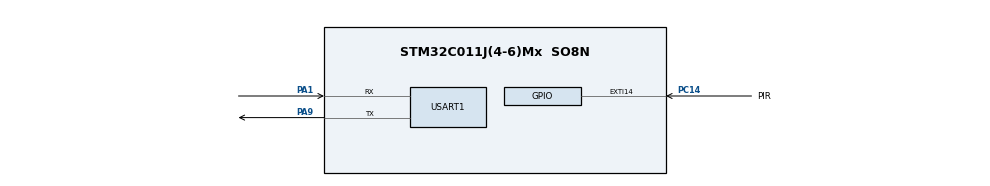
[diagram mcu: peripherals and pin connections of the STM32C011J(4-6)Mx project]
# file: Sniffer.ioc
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Dma.Request0=USART1_TX
Dma.USART1_TX.0.Direction=DMA_MEMORY_TO_PERIPH
Dma.USART1_TX.0.EventEnable=DISABLE
Dma.USART1_TX.0.Instance=DMA1_Channel1
Dma.USART1_TX.0.MemDataAlignment=DMA_MDATAALIGN_BYTE
Dma.USART1_TX.0.MemInc=DMA_MINC_ENABLE
Dma.USART1_TX.0.Mode=DMA_NORMAL
Dma.USART1_TX.0.PeriphDataAlignment=DMA_PDATAALIGN_BYTE
Dma.USART1_TX.0.PeriphInc=DMA_PINC_DISABLE
Dma.USART1_TX.0.Polarity=HAL_DMAMUX_REQ_GEN_RISING
Dma.USART1_TX.0.Priority=DMA_PRIORITY_LOW
Dma.USART1_TX.0.RequestNumber=1
Dma.USART1_TX.0.SignalID=NONE
Dma.USART1_TX.0.SyncEnable=DISABLE
Dma.USART1_TX.0.SyncPolarity=HAL_DMAMUX_SYNC_NO_EVENT
Dma.USART1_TX.0.SyncRequestNumber=1
Dma.USART1_TX.0.SyncSignalID=NONE
Mcu.Family=STM32C0
Mcu.Name=STM32C011J(4-6)Mx
Mcu.Package=SO8N
NVIC.DMA1_Channel1_IRQn=true\:0\:0\:false\:false\:true\:false\:true\:true
NVIC.EXTI4_15_IRQn=true\:0\:0\:false\:false\:true\:true\:true\:true
NVIC.TIM14_IRQn=true\:3\:0\:true\:false\:true\:true\:true\:true
NVIC.TIM16_IRQn=true\:0\:0\:false\:false\:true\:true\:true\:true
PA1.Mode=Asynchronous
PA1.Signal=USART1_RX
PA8__PA11\ [PA9].StandardMode=true
PA9\ [PA11].Mode=Asynchronous
PA9\ [PA11].Signal=USART1_TX
PC14-OSCX_IN\ (PC14).GPIO_Label=PIR
PC14-OSCX_IN\ (PC14).GPIO_ModeDefaultEXTI=GPIO_MODE_IT_RISING_FALLING
PC14-OSCX_IN\ (PC14).Signal=GPXTI14
PC14-OSCX_IN\ (PC14)__PB7.StandardMode=true
PC15-OSCX_OUT\ (PC15)__PA14-BOOT0__PB6.StandardMode=true
PF2-NRST__PA0__PA1__PA2.StandardMode=true
ProjectManager.HeapSize=0x200
ProjectManager.StackSize=0x400
ProjectManager.TargetToolchain=STM32CubeIDE
RCC.ADCFreq_Value=48000000
RCC.AHBFreq_Value=48000000
RCC.CortexFreq_Value=48000000
RCC.EXTERNAL_CLOCK_VALUE=12288000
RCC.HCLKFreq_Value=48000000
RCC.HSE_VALUE=8000000
RCC.HSISYSCLKDivider=RCC_HSI_DIV1
RCC.HSI_VALUE=48000000
RCC.LSE_VALUE=32768
RCC.SYSCLKFreq_VALUE=48000000
TIM14.Period=999
TIM14.Prescaler=47
TIM16.Period=1000
TIM16.Prescaler=47999
TIM3.Prescaler=5
USART1.VirtualMode-Asynchronous=VM_ASYNC
VP_SYS_VS_PINREMAP.Mode=PINREMAP
VP_TIM14_VS_ClockSourceINT.Mode=Enable_Timer
VP_TIM16_VS_ClockSourceINT.Mode=Enable_Timer
VP_TIM3_VS_ClockSourceINT.Mode=Internal
board=custom

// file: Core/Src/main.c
/* USER CODE BEGIN Header */
/**
 ******************************************************************************
 * @file           : main.c
 * @brief          : Main program body
 ******************************************************************************
 * @attention
 *
 * Copyright (c) 2025 STMicroelectronics.
 * All rights reserved.
 *
 * This software is licensed under terms that can be found in the LICENSE file
 * in the root directory of this software component.
 * If no LICENSE file comes with this software, it is provided AS-IS.
 *
 ******************************************************************************
 */
/* USER CODE END Header */
#include "main.h"

/* USER CODE BEGIN Includes */
#include <stdint.h>

/* USER CODE END Includes */

TIM_HandleTypeDef htim3;
TIM_HandleTypeDef htim14;
TIM_HandleTypeDef htim16;

UART_HandleTypeDef huart1;
DMA_HandleTypeDef hdma_usart1_tx;

void SystemClock_Config(void);
static void MX_GPIO_Init(void);
static void MX_DMA_Init(void);
static void MX_TIM3_Init(void);
static void MX_TIM14_Init(void);
static void MX_TIM16_Init(void);
static void MX_USART1_UART_Init(void);

/* USER CODE BEGIN 0 */

void HAL_TIM_PeriodElapsedCallback(TIM_HandleTypeDef *htim)
{
    if (htim->Instance == TIM14) // Verifica se é o TIM2
    {
        // HAL_GPIO_TogglePin(GPIOA, GPIO_PIN_9);
        //  Chamar funções a cada 1ms
        processPulses();

        if (data_ready)
        {
            // HAL_GPIO_WritePin(GPIOA, GPIO_PIN_9,GPIO_PIN_SET);
            analyze_pulses();
            data_ready = 0; // Reseta a flag após o uso
        }

        else if (decode_ready)
        {
            convert_duty_to_bits();
            decode_ready = 0; // Reseta a flag após o uso
        }

        else if (payload_ready)
        {

            analyze_payload();
            payload_ready = 0;
            // HAL_GPIO_WritePin(GPIOA, GPIO_PIN_9,GPIO_PIN_RESET);
        }
        else if (message_done){
        	send_uart_data();
        }
    }

#ifdef DEBUG
    if (htim->Instance == TIM16)
    {
    	sample_count = 0;
    }
#endif
}

/* USER CODE END 0 */

int main(void)
{

  /* MCU Configuration--------------------------------------------------------*/

  /* Reset of all peripherals, Initializes the Flash interface and the Systick. */
  HAL_Init();

  /* Configure the system clock */
  SystemClock_Config();

  /* Initialize all configured peripherals */
  MX_GPIO_Init();
  MX_DMA_Init();
  MX_TIM3_Init();
  MX_TIM14_Init();
  MX_TIM16_Init();
  MX_USART1_UART_Init();
  /* USER CODE BEGIN 2 */
    // HAL_TIM_IC_Start_IT(&htim3, TIM_CHANNEL_2);
    HAL_TIM_Base_Start(&htim3);
    HAL_TIM_Base_Start_IT(&htim14);
#ifdef DEBUG
    HAL_TIM_Base_Start_IT(&htim16);
#endif
    setTimerPulses(&htim3);
    setUart(&huart1);
  /* USER CODE END 2 */

  /* Infinite loop */
  /* USER CODE BEGIN WHILE */
    while (1)
    {
        //    	button_polling(); // Verifica o estado do botão
        //
        //        if (data_ready)
        //        {
        //            process_pulses(); // Processa os pulsos capturados
        //        }

    /* USER CODE END WHILE */

    }
}

void SystemClock_Config(void)
{
  RCC_OscInitTypeDef RCC_OscInitStruct = {0};
  RCC_ClkInitTypeDef RCC_ClkInitStruct = {0};

  __HAL_FLASH_SET_LATENCY(FLASH_LATENCY_1);

  /** Initializes the RCC Oscillators according to the specified parameters
  * in the RCC_OscInitTypeDef structure.
  */
  RCC_OscInitStruct.OscillatorType = RCC_OSCILLATORTYPE_HSI;
  RCC_OscInitStruct.HSIState = RCC_HSI_ON;
  RCC_OscInitStruct.HSIDiv = RCC_HSI_DIV1;
  RCC_OscInitStruct.HSICalibrationValue = RCC_HSICALIBRATION_DEFAULT;
  if (HAL_RCC_OscConfig(&RCC_OscInitStruct) != HAL_OK)
  {
    Error_Handler();
  }

  /** Initializes the CPU, AHB and APB buses clocks
  */
  RCC_ClkInitStruct.ClockType = RCC_CLOCKTYPE_HCLK|RCC_CLOCKTYPE_SYSCLK
                              |RCC_CLOCKTYPE_PCLK1;
  RCC_ClkInitStruct.SYSCLKSource = RCC_SYSCLKSOURCE_HSI;
  RCC_ClkInitStruct.SYSCLKDivider = RCC_SYSCLK_DIV1;
  RCC_ClkInitStruct.AHBCLKDivider = RCC_HCLK_DIV1;
  RCC_ClkInitStruct.APB1CLKDivider = RCC_APB1_DIV1;

  if (HAL_RCC_ClockConfig(&RCC_ClkInitStruct, FLASH_LATENCY_1) != HAL_OK)
  {
    Error_Handler();
  }
}

static void MX_TIM3_Init(void)
{

  TIM_ClockConfigTypeDef sClockSourceConfig = {0};
  TIM_MasterConfigTypeDef sMasterConfig = {0};

  htim3.Instance = TIM3;
  htim3.Init.Prescaler = 5;
  htim3.Init.CounterMode = TIM_COUNTERMODE_UP;
  htim3.Init.Period = 65535;
  htim3.Init.ClockDivision = TIM_CLOCKDIVISION_DIV1;
  htim3.Init.AutoReloadPreload = TIM_AUTORELOAD_PRELOAD_DISABLE;
  if (HAL_TIM_Base_Init(&htim3) != HAL_OK)
  {
    Error_Handler();
  }
  sClockSourceConfig.ClockSource = TIM_CLOCKSOURCE_INTERNAL;
  if (HAL_TIM_ConfigClockSource(&htim3, &sClockSourceConfig) != HAL_OK)
  {
    Error_Handler();
  }
  sMasterConfig.MasterOutputTrigger = TIM_TRGO_RESET;
  sMasterConfig.MasterSlaveMode = TIM_MASTERSLAVEMODE_DISABLE;
  if (HAL_TIMEx_MasterConfigSynchronization(&htim3, &sMasterConfig) != HAL_OK)
  {
    Error_Handler();
  }

}

static void MX_TIM14_Init(void)
{

  htim14.Instance = TIM14;
  htim14.Init.Prescaler = 47;
  htim14.Init.CounterMode = TIM_COUNTERMODE_UP;
  htim14.Init.Period = 999;
  htim14.Init.ClockDivision = TIM_CLOCKDIVISION_DIV1;
  htim14.Init.AutoReloadPreload = TIM_AUTORELOAD_PRELOAD_DISABLE;
  if (HAL_TIM_Base_Init(&htim14) != HAL_OK)
  {
    Error_Handler();
  }

}

static void MX_TIM16_Init(void)
{

  htim16.Instance = TIM16;
  htim16.Init.Prescaler = 47999;
  htim16.Init.CounterMode = TIM_COUNTERMODE_UP;
  htim16.Init.Period = 1000;
  htim16.Init.ClockDivision = TIM_CLOCKDIVISION_DIV1;
  htim16.Init.RepetitionCounter = 0;
  htim16.Init.AutoReloadPreload = TIM_AUTORELOAD_PRELOAD_DISABLE;
  if (HAL_TIM_Base_Init(&htim16) != HAL_OK)
  {
    Error_Handler();
  }

}

static void MX_USART1_UART_Init(void)
{

  huart1.Instance = USART1;
  huart1.Init.BaudRate = 115200;
  huart1.Init.WordLength = UART_WORDLENGTH_8B;
  huart1.Init.StopBits = UART_STOPBITS_1;
  huart1.Init.Parity = UART_PARITY_NONE;
  huart1.Init.Mode = UART_MODE_TX_RX;
  huart1.Init.HwFlowCtl = UART_HWCONTROL_NONE;
  huart1.Init.OverSampling = UART_OVERSAMPLING_16;
  huart1.Init.OneBitSampling = UART_ONE_BIT_SAMPLE_DISABLE;
  huart1.Init.ClockPrescaler = UART_PRESCALER_DIV1;
  huart1.AdvancedInit.AdvFeatureInit = UART_ADVFEATURE_NO_INIT;
  if (HAL_UART_Init(&huart1) != HAL_OK)
  {
    Error_Handler();
  }
  if (HAL_UARTEx_SetTxFifoThreshold(&huart1, UART_TXFIFO_THRESHOLD_1_8) != HAL_OK)
  {
    Error_Handler();
  }
  if (HAL_UARTEx_SetRxFifoThreshold(&huart1, UART_RXFIFO_THRESHOLD_1_8) != HAL_OK)
  {
    Error_Handler();
  }
  if (HAL_UARTEx_DisableFifoMode(&huart1) != HAL_OK)
  {
    Error_Handler();
  }

}

static void MX_DMA_Init(void)
{

  /* DMA controller clock enable */
  __HAL_RCC_DMA1_CLK_ENABLE();

  /* DMA interrupt init */
  /* DMA1_Channel1_IRQn interrupt configuration */
  HAL_NVIC_SetPriority(DMA1_Channel1_IRQn, 0, 0);
  HAL_NVIC_EnableIRQ(DMA1_Channel1_IRQn);

}

static void MX_GPIO_Init(void)
{
  GPIO_InitTypeDef GPIO_InitStruct = {0};

  /* GPIO Ports Clock Enable */
  __HAL_RCC_GPIOC_CLK_ENABLE();
  __HAL_RCC_GPIOA_CLK_ENABLE();

  /*Configure GPIO pin : PIR_Pin */
  GPIO_InitStruct.Pin = PIR_Pin;
  GPIO_InitStruct.Mode = GPIO_MODE_IT_RISING_FALLING;
  GPIO_InitStruct.Pull = GPIO_NOPULL;
  HAL_GPIO_Init(PIR_GPIO_Port, &GPIO_InitStruct);

  /* EXTI interrupt init*/
  HAL_NVIC_SetPriority(EXTI4_15_IRQn, 0, 0);
  HAL_NVIC_EnableIRQ(EXTI4_15_IRQn);

}

void Error_Handler(void)
{
    __disable_irq();
    while (1)
    {
    }
}
